# STM32WL54xx register map
File version: 1.0
Registers are 32-bit, read-write, reset 0x0 unless marked. A register's access mark holds for its fields unless they carry their own. Offsets are from the block's base; [hi:lo] are bit positions; {n}, {i} and the like mark numbered series; 'fields as' and 'values as' point back to an identical list.

## PWR — Power Control
Base 0x58000400
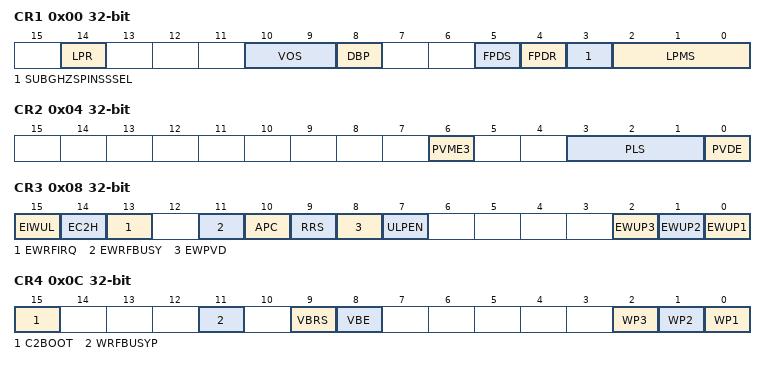
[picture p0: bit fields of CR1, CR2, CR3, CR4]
0x00 CR1 — PWR Power Control Register 1
  [14] LPR — Regulator Low-Power Run mode
  [10:9] VOS — Voltage scaling range selection
    1=SCALE1; 2=SCALE2
  [8] DBP — Disable Backup Domain write protection
  [5] FPDS — Flash power down mode during LPsleep for CPU1
    0=IDLE; 1=POWER_DOWN
  [4] FPDR — Flash power down mode during LPrun for CPU1
    0=IDLE; 1=POWER_DOWN
  [3] SUBGHZSPINSSSEL — Sub-GHz radio SPI NSS source select
    0=SW (Sub-GHz radio SPI NSS controlled by software. Refer to function @ref LL_PWR_UnselectSUBGHZSPI_NSS().); 1=LPTIM3 (Sub-GHz radio SPI NSS controlled by LPTIM3.)
  [2:0] LPMS — Low Power Mode Selection for CPU1
    0=STOP0; 1=STOP1; 2=STOP2; 3=STANDBY; 7=SHUTDOWN
0x04 CR2 — PWR Power Control Register 2
  [6] PVME3 — Peripherical Voltage Monitor Vdda Enable
  [3:1] PLS — Power voltage detector level selection
    {v}=PVDLEVEL_{v} (v=0..7)
  [0] PVDE — Power voltage detector enable
0x08 CR3 — PWR Power Control Register 3
  [15] EIWUL — Internal Wake-Up line interrupt for CPU1
  [14] EC2H — CPU2 Hold interrupt for CPU1
  [13] EWRFIRQ — Enable Radio IRQ[2:0] and wake-up for CPU1
    0=NONE (Radio IRQ trigger action: no wake-up from low-power mode and no interruption sent to the selected CPU.); 1=WU_IT (Radio IRQ trigger action: wake-up from low-power mode Standby and interruption sent to the selected CPU.)
  [11] EWRFBUSY — Enable Radio busy IRQ and wake-up for CPU1
    0=NONE (Radio busy trigger action: no wake-up from low-power mode and no interruption sent to the selected CPU.); 1=WU_IT (Radio busy trigger action: wake-up from low-power mode Standby and interruption sent to the selected CPU.)
  [10] APC — Apply pull-up and pull-down configuration for CPU1
  [9] RRS — SRAM2 retention in STANDBY mode
  [8] EWPVD — Enable wakeup PVD for CPU1
  [7] ULPEN — Enable periodical sampling of supply voltage in Stop and Standby modes for detecting condition of PDR and BOR reset
  [2] EWUP3 — Enable external WKUP Pin 3 [line 2]
  [1] EWUP2 — Enable external WKUP Pin 2 [line 1]
  [0] EWUP1 — Enable external WKUP Pin 1 [line 0]
0x0C CR4 — PWR Power Control Register 4
  [15] C2BOOT — Boot CPU2 after reset or wakeup from Stop or Standby modes
  [11] WRFBUSYP — Wake-up radio busy polarity
    0=RISING (Radio busy signal polarity to rising edge (detection on high level).); 1=FALLING (Radio busy signal polarity to falling edge (detection on low level).)
  [9] VBRS — VBAT battery charging resistor selection
    0=CHARG_RESISTOR_5K; 1=CHARGRESISTOR_1_5K
  [8] VBE — VBAT battery charging enable
  [2] WP3 — Wake-Up Pin 3 [line 2] polarity
  [1] WP2 — Wake-Up Pin 2 [line 1] polarity
  [0] WP1 — Wake-Up Pin 1 [line 0] polarity
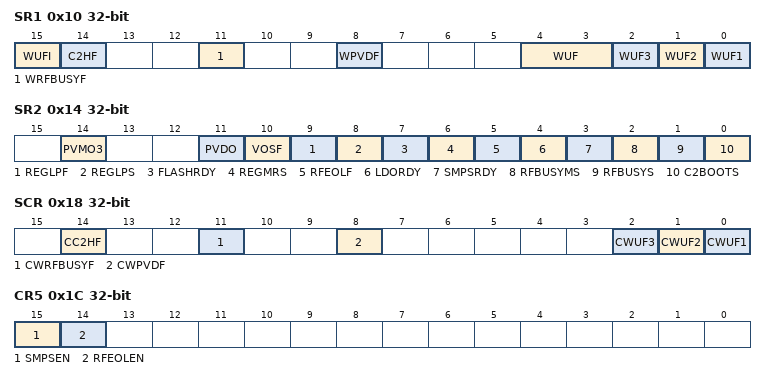
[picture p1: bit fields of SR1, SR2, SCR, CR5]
0x10 SR1 — PWR Power Status Register 1
  [15] WUFI — Internal wakeup interrupt flag
  [14] C2HF — CPU2 Hold interrupt flag
  [11] WRFBUSYF — Wakeup radio busy flag
  [8] WPVDF — Wakeup PVD flag
  [4:3] WUF — Wakeup Flags of all pins
  [2] WUF3 — Wakeup Pin 3 [Flag 2]
  [1] WUF2 — Wakeup Pin 2 [Flag 1]
  [0] WUF1 — Wakeup Pin 1 [Flag 0]
0x14 SR2 — PWR Power Status Register 2
  [14] PVMO3 — Peripheral voltage monitor output 3: VDDA vs. 1.62V
  [11] PVDO — Power voltage detector output
  [10] VOSF — Voltage scaling flag
  [9] REGLPF — Low-power regulator being used
  [8] REGLPS — Low-power regulator ready
  [7] FLASHRDY — Flash ready
  [6] REGMRS — Main regulator status
  [5] RFEOLF — Radio end of life flag
  [4] LDORDY — LDO ready flag
  [3] SMPSRDY — SMPS ready flag
  [2] RFBUSYMS — Radio busy masked signal status
  [1] RFBUSYS — Radio busy signal status
  [0] C2BOOTS — CPU2 boot or wakeup request source information
0x18 SCR — PWR Power Status Reset Register
  [14] CC2HF — Clear CPU2 Hold interrupt flag
  [11] CWRFBUSYF — Clear Radio busy interrupt flag
  [8] CWPVDF — Clear wakeup PVD interrupt flag
  [2] CWUF3 — Clear Wake-up Pin 3 [Flag 2]
  [1] CWUF2 — Clear Wake-up Pin 2 [Flag 1]
  [0] CWUF1 — Clear Wake-up Pin 1 [Flag 0]
0x1C CR5 — PWR Power Control Register 5
  [15] SMPSEN — Enable SMPS Step Down converter SMPS mode enable
    0=BYPASS (SMPS step down in bypass mode (disable).); 1=STEP_DOWN (SMPS step down in step down mode if system low power mode is run, LP run or Stop 0. If system low power mode is Stop 1, Stop 2, Standby, Shutdown, then SMPS is forced in mode open to preserve energy stored in decoupling capacitor as long as possible. Note: In case of a board without SMPS coil mounted, SMPS should not be activated.)
  [14] RFEOLEN — Enable Radio End Of Life detector enabled
    0=DISABLE (Monitoring of supply voltage for radio operating level (radio End Of Life) disable); 1=ENABLE (Monitoring of supply voltage for radio operating level (radio End Of Life) enable)
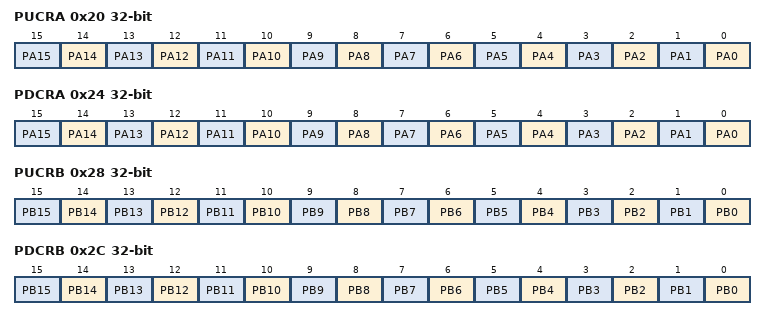
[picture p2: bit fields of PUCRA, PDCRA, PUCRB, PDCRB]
0x20 PUCRA — PWR Pull-Up Control Register of port A
  [n] PA{n} (n=0..15) — Pin PA{n} Pull-Up set
0x24 PDCRA — PWR Pull-Down Control Register of port A
  [n] PA{n} (n=0..15) — Pin PA{n} Pull-Down set
0x28 PUCRB — PWR Pull-Up Control Register of port B
  [n] PB{n} (n=0..15) — Pin PB{n} Pull-Up set
0x2C PDCRB — PWR Pull-Down Control Register of port B
  [n] PB{n} (n=0..15) — Pin PB{n} Pull-Down set
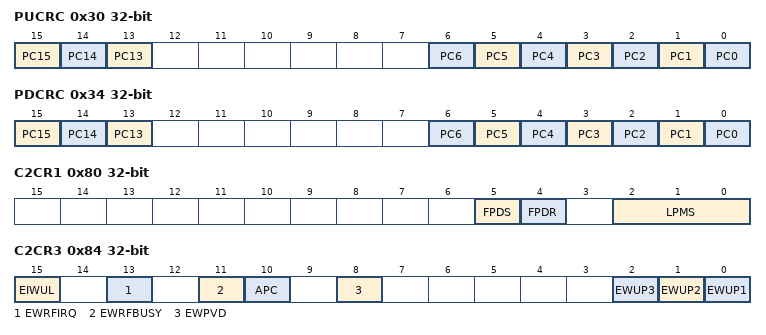
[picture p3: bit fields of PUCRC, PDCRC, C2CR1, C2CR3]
0x30 PUCRC — PWR Pull-Up Control Register of port C
  [15] PC15 — Pin PC15 Pull-Up set
  [14] PC14 — Pin PC14 Pull-Up set
  [13] PC13 — Pin PC13 Pull-Up set
  [n] PC{n} (n=0..6) — Pin PC{n} Pull-Up set
0x34 PDCRC — PWR Pull-Down Control Register of port C
  [15] PC15 — Pin PC15 Pull-Down set
  [14] PC14 — Pin PC14 Pull-Down set
  [13] PC13 — Pin PC13 Pull-Down set
  [n] PC{n} (n=0..6) — Pin PC{n} Pull-Down set
0x58 PUCRH — PWR Pull-Up Control Register of port H
  [3] PH3 — Pin PH3 Pull-Up set
0x5C PDCRH — PWR Pull-Down Control Register of port H
  [3] PH3 — Pin PH3 Pull-Down set
0x80 C2CR1 — PWR Power Control Register 1 for CPU2
  [5] FPDS — Flash power down mode during LPsleep for CPU2
    0=IDLE; 1=POWER_DOWN
  [4] FPDR — Flash power down mode during LPrun for CPU2
    0=IDLE; 1=POWER_DOWN
  [2:0] LPMS — Low Power Mode Selection for CPU2
    0=STOP0; 1=STOP1; 2=STOP2; 3=STANDBY; 7=SHUTDOWN
0x84 C2CR3 — PWR Power Control Register 3 for CPU2
  [15] EIWUL — Internal Wake-Up line interrupt for CPU2
  [13] EWRFIRQ — Enable Radio IRQ[2:0] and wake-up for CPU2
    values as CR3.EWRFIRQ
  [11] EWRFBUSY — Enable Radio busy IRQ and wake-up for CPU2
    values as CR3.EWRFBUSY
  [10] APC — Apply pull-up and pull-down configuration for CPU2
  [8] EWPVD — Enable wakeup PVD for CPU2
  [2] EWUP3 — Enable external WKUP Pin 3 [line 2] for CPU2
  [1] EWUP2 — Enable external WKUP Pin 2 [line 1] for CPU2
  [0] EWUP1 — Enable external WKUP Pin 1 [line 0] for CPU2
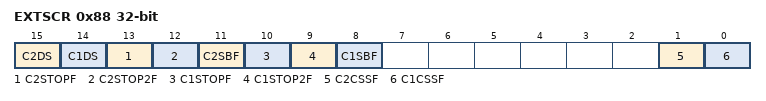
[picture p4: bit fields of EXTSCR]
0x88 EXTSCR — PWR Power Status Reset Register for CPU2
  [15] C2DS — CPU2 deepsleep mode flag
  [14] C1DS — CPU1 deepsleep mode flag
  [13] C2STOPF — System stop0 or stop1 flag for CPU2
  [12] C2STOP2F — System stop2 flag for CPU2
  [11] C2SBF — System standby flag for CPU2
  [10] C1STOPF — System stop0 or stop1 flag for CPU1
  [9] C1STOP2F — System stop2 flag for CPU1
  [8] C1SBF — System standby flag for CPU1
  [1] C2CSSF — Clear standby and stop flags for CPU2
  [0] C1CSSF — Clear standby and stop flags for CPU1
0x8C SECCFGR — PWR Security Configuration Register
  [15] C2EWILA — CPU2 illegal access interrupt enable
0x90 SUBGHZSPICR — PWR SUBGHZSPI Control Register
  [15] NSS — Sub-GHz radio SUBGHZSPI_NSS control
0x98 RSSCMDR — PWR RSS Command Register
  [7:0] RSSCMD — RSS command
